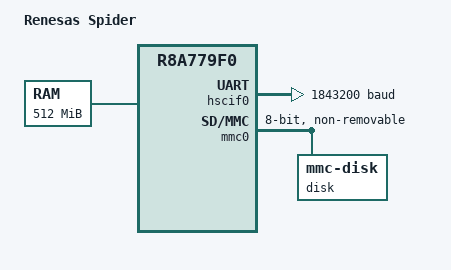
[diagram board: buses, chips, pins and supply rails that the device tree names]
/*
 * Copyright (c) 2023 EPAM Systems
 *
 * SPDX-License-Identifier: Apache-2.0
 *
 */

/dts-v1/;
#include <mem.h>
#include <arm64/renesas/r8a779f0.dtsi>
#include "spider-pinctrl.dtsi"

/ {
	model = "Renesas Spider";
	chosen {
		zephyr,sram = &ram;
		zephyr,console = &hscif0;
		zephyr,shell-uart = &hscif0;
	};

	/* These aliases are provided for compatibility with samples */
	aliases {
		sdhc0 = &mmc0;
	};

	ram: memory@48000000 {
		device_type = "mmio-sram";
		reg = <0x0 0x48000000 0x0 DT_SIZE_M(512)>;
	};
};

&hscif0 {
	pinctrl-0 = <&hscif0_data_tx_default &hscif0_data_rx_default &hscif0_rts_default &hscif0_cts_default>;
	pinctrl-names = "default";
	current-speed = <1843200>;
	status = "okay";
};

&mmc0 {
	pinctrl-0 = <&mmc_clk &mmc_cmd &mmc_ds
		&mmc_data0 &mmc_data1 &mmc_data2 &mmc_data3
		&mmc_data4 &mmc_data5 &mmc_data6 &mmc_data7>;
	pinctrl-1 = <&mmc_clk &mmc_cmd &mmc_ds
		&mmc_data0 &mmc_data1 &mmc_data2 &mmc_data3
		&mmc_data4 &mmc_data5 &mmc_data6 &mmc_data7>;
	pinctrl-names = "default", "uhs";
	disk {
		compatible = "zephyr,mmc-disk";
		status = "okay";
	};
	
	bus-width = <8>;
	mmc-hs200-1_8v;
	mmc-hs400-1_8v;
	non-removable;
	status = "okay";
};
